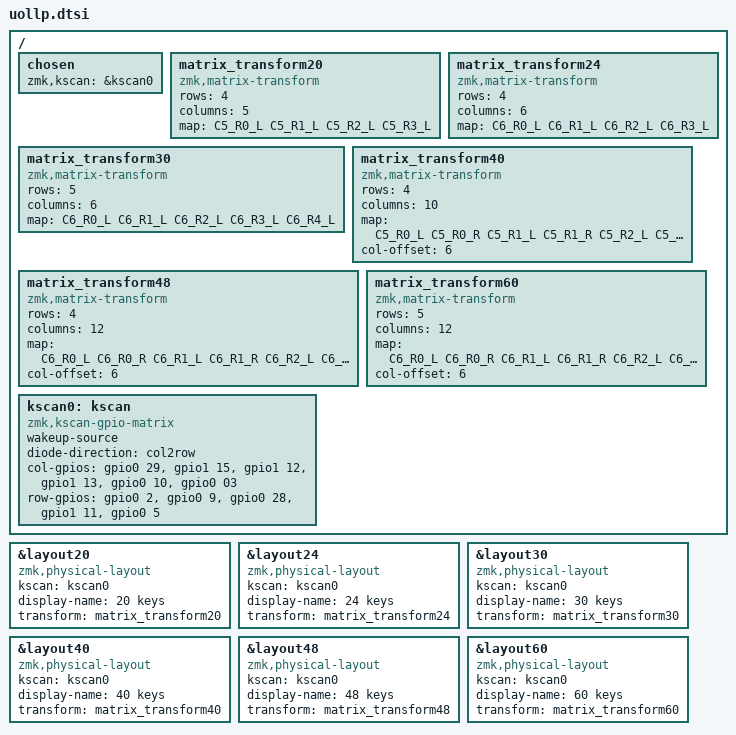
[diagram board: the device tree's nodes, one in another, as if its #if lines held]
#include <physical_layouts.dtsi>
#include <dt-bindings/zmk/matrix_transform.h>
#include "uollp_layout.dtsi"

#define C5_R0_L RC(0,1) RC(0,2) RC(0,3) RC(0,4) RC(0,5)
#define C5_R0_R RC(0,7) RC(0,8) RC(0,9) RC(0,10) RC(0,11)
#define C5_R1_L RC(1,1) RC(1,2) RC(1,3) RC(1,4) RC(1,5)
#define C5_R1_R RC(1,7) RC(1,8) RC(1,9) RC(1,10) RC(1,11)
#define C5_R2_L RC(2,1) RC(2,2) RC(2,3) RC(2,4) RC(2,5)
#define C5_R2_R RC(2,7) RC(2,8) RC(2,9) RC(2,10) RC(2,11)
#define C5_R3_L RC(3,1) RC(3,2) RC(3,3) RC(3,4) RC(3,5)
#define C5_R3_R RC(3,7) RC(3,8) RC(3,9) RC(3,10) RC(3,11)

#define C6_R0_L RC(0,0) RC(0,1) RC(0,2) RC(0,3) RC(0,4) RC(0,5)
#define C6_R0_R RC(0,6) RC(0,7) RC(0,8) RC(0,9) RC(0,10) RC(0,11)
#define C6_R1_L RC(1,0) RC(1,1) RC(1,2) RC(1,3) RC(1,4) RC(1,5)
#define C6_R1_R RC(1,6) RC(1,7) RC(1,8) RC(1,9) RC(1,10) RC(1,11)
#define C6_R2_L RC(2,0) RC(2,1) RC(2,2) RC(2,3) RC(2,4) RC(2,5)
#define C6_R2_R RC(2,6) RC(2,7) RC(2,8) RC(2,9) RC(2,10) RC(2,11)
#define C6_R3_L RC(3,0) RC(3,1) RC(3,2) RC(3,3) RC(3,4) RC(3,5)
#define C6_R3_R RC(3,6) RC(3,7) RC(3,8) RC(3,9) RC(3,10) RC(3,11)
#define C6_R4_L RC(4,0) RC(4,1) RC(4,2) RC(4,3) RC(4,4) RC(4,5)
#define C6_R4_R RC(4,6) RC(4,7) RC(4,8) RC(4,9) RC(4,10) RC(4,11)

/ {
    chosen {
        
        zmk,kscan = &kscan0;
    };

    matrix_transform20: matrix_transform20 {

        compatible = "zmk,matrix-transform";
        rows = <4>;
        columns = <5>;
        map = <C5_R0_L C5_R1_L C5_R2_L C5_R3_L>;
    };

    matrix_transform24: matrix_transform24 {

        compatible = "zmk,matrix-transform";
        rows = <4>;
        columns = <6>;
        map = <C6_R0_L C6_R1_L C6_R2_L C6_R3_L>;
    };

    matrix_transform30: matrix_transform30 {

        compatible = "zmk,matrix-transform";
        rows = <5>;
        columns = <6>;
        map = <C6_R0_L C6_R1_L C6_R2_L C6_R3_L C6_R4_L>;
    };

    matrix_transform40: matrix_transform40 {

        compatible = "zmk,matrix-transform";
        rows = <4>;
        columns = <10>;
        map = <C5_R0_L C5_R0_R C5_R1_L C5_R1_R C5_R2_L C5_R2_R C5_R3_L C5_R3_R>;
#if defined(ZMK_SPLIT) && !defined(ZMK_SPLIT_ROLE_CENTRAL)
        col-offset = <6>;
#endif
    };

    matrix_transform48: matrix_transform48 {

        compatible = "zmk,matrix-transform";
        rows = <4>;
        columns = <12>;
        map = <C6_R0_L C6_R0_R C6_R1_L C6_R1_R C6_R2_L C6_R2_R C6_R3_L C6_R3_R>;
#if defined(ZMK_SPLIT) && !defined(ZMK_SPLIT_ROLE_CENTRAL)
        col-offset = <6>;
#endif
    };

    matrix_transform60: matrix_transform60 {

        compatible = "zmk,matrix-transform";
        rows = <5>;
        columns = <12>;
        map = <C6_R0_L C6_R0_R C6_R1_L C6_R1_R C6_R2_L C6_R2_R C6_R3_L C6_R3_R C6_R4_L C6_R4_R>;
#if defined(ZMK_SPLIT) && !defined(ZMK_SPLIT_ROLE_CENTRAL)
        col-offset = <6>;
#endif
    };

    kscan0: kscan {

        compatible = "zmk,kscan-gpio-matrix";
        wakeup-source;
        diode-direction = "col2row";
        col-gpios
            = <&gpio0 29 GPIO_ACTIVE_HIGH>
            , <&gpio1 15 GPIO_ACTIVE_HIGH>
            , <&gpio1 12 GPIO_ACTIVE_HIGH>
            , <&gpio1 13 GPIO_ACTIVE_HIGH>
            , <&gpio0 10 GPIO_ACTIVE_HIGH>
            , <&gpio0 03 GPIO_ACTIVE_HIGH>
        ;
        row-gpios
            = <&gpio0  2 (GPIO_ACTIVE_HIGH | GPIO_PULL_DOWN)>
            , <&gpio0  9 (GPIO_ACTIVE_HIGH | GPIO_PULL_DOWN)>
            , <&gpio0 28 (GPIO_ACTIVE_HIGH | GPIO_PULL_DOWN)>
            , <&gpio1 11 (GPIO_ACTIVE_HIGH | GPIO_PULL_DOWN)>
            , <&gpio0  5 (GPIO_ACTIVE_HIGH | GPIO_PULL_DOWN)>
        ;
    };
};

&layout20 {

    compatible = "zmk,physical-layout";
    kscan = <&kscan0>;
    display-name = "20 keys";
    transform = <&matrix_transform20>;
};

&layout24 {

    compatible = "zmk,physical-layout";
    kscan = <&kscan0>;
    display-name = "24 keys";
    transform = <&matrix_transform24>;
};

&layout30 {
    
    compatible = "zmk,physical-layout";
    kscan = <&kscan0>;
    display-name = "30 keys";
    transform = <&matrix_transform30>;
};

&layout40 {

    compatible = "zmk,physical-layout";
    kscan = <&kscan0>;
    display-name = "40 keys";
    transform = <&matrix_transform40>;
};

&layout48 {

    compatible = "zmk,physical-layout";
    kscan = <&kscan0>;
    display-name = "48 keys";
    transform = <&matrix_transform48>;
};

&layout60 {
    
    compatible = "zmk,physical-layout";
    kscan = <&kscan0>;
    display-name = "60 keys";
    transform = <&matrix_transform60>;
};
